# TM4C129ENCPDT register map
File version: 1.0
CPU: CORTEX_M4 1.0, other endian, MPU, FPU, 3 interrupt priority bits
Registers are 32-bit, read-write, reset 0x0 unless marked. A register's access mark holds for its fields unless they carry their own. Offsets are from the block's base; [hi:lo] are bit positions; {n}, {i} and the like mark numbered series.

## HIB — Hibernation module register addresses
Base 0x400FC000
0x00 HIB_RTCC — Hibernation RTC Counter
  [31:0] HIB_RTCC — [31:0] RTC Counter
0x04 HIB_RTCM0 — Hibernation RTC Match 0
  [31:0] HIB_RTCM0 — [31:0] RTC Match 0
0x0C HIB_RTCLD — Hibernation RTC Load
  [31:0] HIB_RTCLD — [31:0] RTC Load
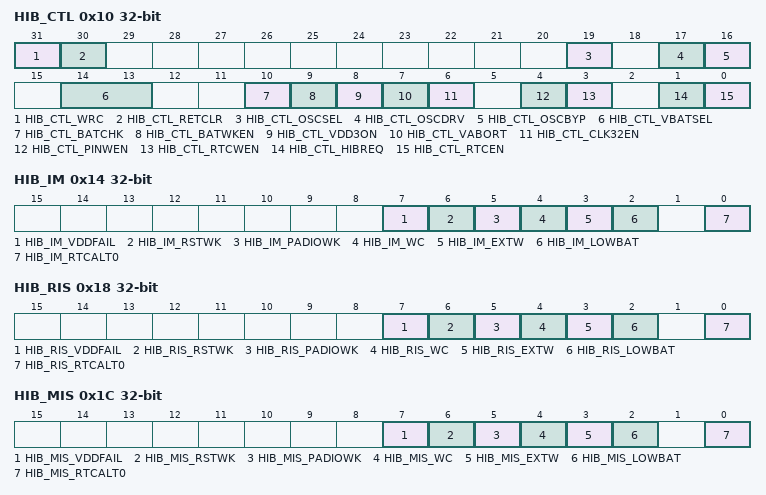
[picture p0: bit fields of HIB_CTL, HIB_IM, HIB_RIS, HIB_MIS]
0x10 HIB_CTL — Hibernation Control
  [31] HIB_CTL_WRC — [31:31] Write Complete/Capable
  [30] HIB_CTL_RETCLR — [30:30] GPIO Retention/Clear
  [19] HIB_CTL_OSCSEL — [19:19] Oscillator Select
  [17] HIB_CTL_OSCDRV — [17:17] Oscillator Drive Capability
  [16] HIB_CTL_OSCBYP — [16:16] Oscillator Bypass
  [14:13] HIB_CTL_VBATSEL — [14:13] Select for Low-Battery Comparator
    0=HIB_CTL_VBATSEL_1_9V (1.9 Volts); 0x2000=HIB_CTL_VBATSEL_2_1V (2.1 Volts (default)); 0x4000=HIB_CTL_VBATSEL_2_3V (2.3 Volts); 0x6000=HIB_CTL_VBATSEL_2_5V (2.5 Volts)
  [10] HIB_CTL_BATCHK — [10:10] Check Battery Status
  [9] HIB_CTL_BATWKEN — [9:9] Wake on Low Battery
  [8] HIB_CTL_VDD3ON — [8:8] VDD Powered
  [7] HIB_CTL_VABORT — [7:7] Power Cut Abort Enable
  [6] HIB_CTL_CLK32EN — [6:6] Clocking Enable
  [4] HIB_CTL_PINWEN — [4:4] External Wake Pin Enable
  [3] HIB_CTL_RTCWEN — [3:3] RTC Wake-up Enable
  [1] HIB_CTL_HIBREQ — [1:1] Hibernation Request
  [0] HIB_CTL_RTCEN — [0:0] RTC Timer Enable
0x14 HIB_IM — Hibernation Interrupt Mask
  [7] HIB_IM_VDDFAIL — [7:7] VDD Fail Interrupt Mask
  [6] HIB_IM_RSTWK — [6:6] Reset Pad I/O Wake-Up Interrupt Mask
  [5] HIB_IM_PADIOWK — [5:5] Pad I/O Wake-Up Interrupt Mask
  [4] HIB_IM_WC — [4:4] External Write Complete/Capable Interrupt Mask
  [3] HIB_IM_EXTW — [3:3] External Wake-Up Interrupt Mask
  [2] HIB_IM_LOWBAT — [2:2] Low Battery Voltage Interrupt Mask
  [0] HIB_IM_RTCALT0 — [0:0] RTC Alert 0 Interrupt Mask
0x18 HIB_RIS — Hibernation Raw Interrupt Status
  [7] HIB_RIS_VDDFAIL — [7:7] VDD Fail Raw Interrupt Status
  [6] HIB_RIS_RSTWK — [6:6] Reset Pad I/O Wake-Up Raw Interrupt Status
  [5] HIB_RIS_PADIOWK — [5:5] Pad I/O Wake-Up Raw Interrupt Status
  [4] HIB_RIS_WC — [4:4] Write Complete/Capable Raw Interrupt Status
  [3] HIB_RIS_EXTW — [3:3] External Wake-Up Raw Interrupt Status
  [2] HIB_RIS_LOWBAT — [2:2] Low Battery Voltage Raw Interrupt Status
  [0] HIB_RIS_RTCALT0 — [0:0] RTC Alert 0 Raw Interrupt Status
0x1C HIB_MIS — Hibernation Masked Interrupt Status
  [7] HIB_MIS_VDDFAIL — [7:7] VDD Fail Interrupt Mask
  [6] HIB_MIS_RSTWK — [6:6] Reset Pad I/O Wake-Up Interrupt Mask
  [5] HIB_MIS_PADIOWK — [5:5] Pad I/O Wake-Up Interrupt Mask
  [4] HIB_MIS_WC — [4:4] Write Complete/Capable Masked Interrupt Status
  [3] HIB_MIS_EXTW — [3:3] External Wake-Up Masked Interrupt Status
  [2] HIB_MIS_LOWBAT — [2:2] Low Battery Voltage Masked Interrupt Status
  [0] HIB_MIS_RTCALT0 — [0:0] RTC Alert 0 Masked Interrupt Status
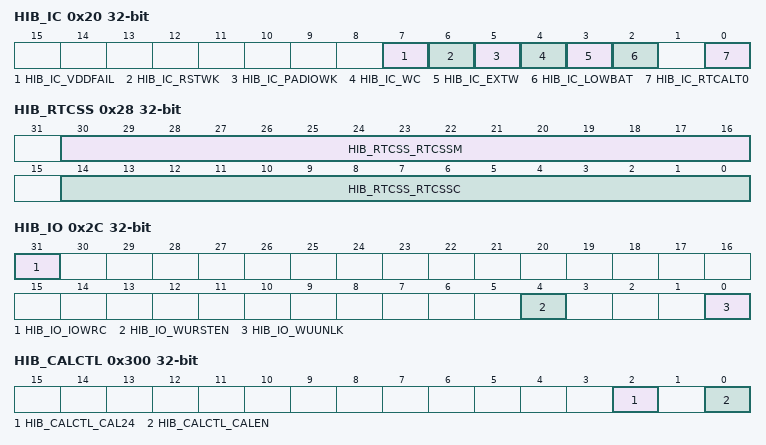
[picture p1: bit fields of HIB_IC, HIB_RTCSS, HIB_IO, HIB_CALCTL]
0x20 HIB_IC — Hibernation Interrupt Clear
  [7] HIB_IC_VDDFAIL — [7:7] VDD Fail Interrupt Clear
  [6] HIB_IC_RSTWK — [6:6] Reset Pad I/O Wake-Up Interrupt Clear
  [5] HIB_IC_PADIOWK — [5:5] Pad I/O Wake-Up Interrupt Clear
  [4] HIB_IC_WC — [4:4] Write Complete/Capable Interrupt Clear
  [3] HIB_IC_EXTW — [3:3] External Wake-Up Interrupt Clear
  [2] HIB_IC_LOWBAT — [2:2] Low Battery Voltage Interrupt Clear
  [0] HIB_IC_RTCALT0 — [0:0] RTC Alert0 Masked Interrupt Clear
0x24 HIB_RTCT — Hibernation RTC Trim
  [15:0] HIB_RTCT_TRIM — [15:0] RTC Trim Value
0x28 HIB_RTCSS — Hibernation RTC Sub Seconds
  [30:16] HIB_RTCSS_RTCSSM — [30:16] RTC Sub Seconds Match
  [14:0] HIB_RTCSS_RTCSSC — [14:0] RTC Sub Seconds Count
0x2C HIB_IO — Hibernation IO Configuration
  [31] HIB_IO_IOWRC — [31:31] I/O Write Complete
  [4] HIB_IO_WURSTEN — [4:4] Reset Wake Source Enable
  [0] HIB_IO_WUUNLK — [0:0] I/O Wake Pad Configuration Enable
0x30 HIB_DATA — Hibernation Data
  [31:0] HIB_DATA_RTD — [31:0] Hibernation Module NV Data
0x300 HIB_CALCTL — Hibernation Calendar Control
  [2] HIB_CALCTL_CAL24 — [2:2] Calendar Mode
  [0] HIB_CALCTL_CALEN — [0:0] RTC Calendar/Counter Mode Select
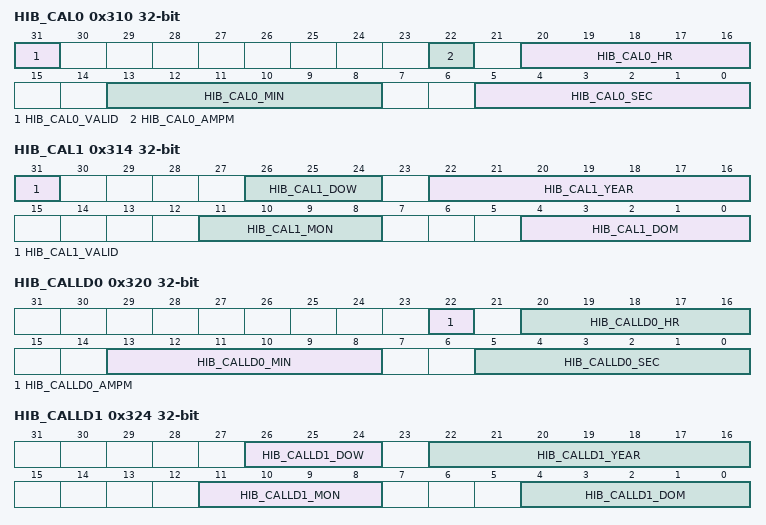
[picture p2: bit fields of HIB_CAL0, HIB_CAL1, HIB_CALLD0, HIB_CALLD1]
0x310 HIB_CAL0 — Hibernation Calendar 0
  [31] HIB_CAL0_VALID — [31:31] Valid Calendar Load
  [22] HIB_CAL0_AMPM — [22:22] AM/PM Designation
  [20:16] HIB_CAL0_HR — [20:16] Hours
  [13:8] HIB_CAL0_MIN — [13:8] Minutes
  [5:0] HIB_CAL0_SEC — [5:0] Seconds
0x314 HIB_CAL1 — Hibernation Calendar 1
  [31] HIB_CAL1_VALID — [31:31] Valid Calendar Load
  [26:24] HIB_CAL1_DOW — [26:24] Day of Week
  [22:16] HIB_CAL1_YEAR — [22:16] Year Value
  [11:8] HIB_CAL1_MON — [11:8] Month
  [4:0] HIB_CAL1_DOM — [4:0] Day of Month
0x320 HIB_CALLD0 — Hibernation Calendar Load 0
  [22] HIB_CALLD0_AMPM — [22:22] AM/PM Designation
  [20:16] HIB_CALLD0_HR — [20:16] Hours
  [13:8] HIB_CALLD0_MIN — [13:8] Minutes
  [5:0] HIB_CALLD0_SEC — [5:0] Seconds
0x324 HIB_CALLD1 — Hibernation Calendar Load
  [26:24] HIB_CALLD1_DOW — [26:24] Day of Week
  [22:16] HIB_CALLD1_YEAR — [22:16] Year Value
  [11:8] HIB_CALLD1_MON — [11:8] Month
  [4:0] HIB_CALLD1_DOM — [4:0] Day of Month
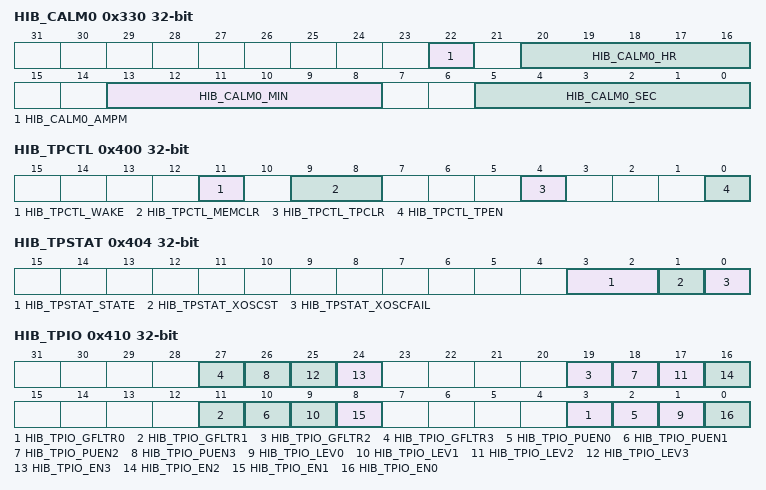
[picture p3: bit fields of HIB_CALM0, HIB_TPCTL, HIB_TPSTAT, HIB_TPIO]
0x330 HIB_CALM0 — Hibernation Calendar Match 0
  [22] HIB_CALM0_AMPM — [22:22] AM/PM Designation
  [20:16] HIB_CALM0_HR — [20:16] Hours
  [13:8] HIB_CALM0_MIN — [13:8] Minutes
  [5:0] HIB_CALM0_SEC — [5:0] Seconds
0x334 HIB_CALM1 — Hibernation Calendar Match 1
  [4:0] HIB_CALM1_DOM — [4:0] Day of Month
0x360 HIB_LOCK — Hibernation Lock
  [31:0] HIB_LOCK_HIBLOCK — [31:0] HIbernate Lock
0x400 HIB_TPCTL — HIB Tamper Control
  [11] HIB_TPCTL_WAKE — [11:11] Wake from Hibernate on a Tamper Event
  [9:8] HIB_TPCTL_MEMCLR — [9:8] HIB Memory Clear on Tamper Event
    0=HIB_TPCTL_MEMCLR_NONE (Do not Clear HIB memory on tamper event); 0x100=HIB_TPCTL_MEMCLR_LOW32 (Clear Lower 32 Bytes of HIB memory on tamper event); 0x200=HIB_TPCTL_MEMCLR_HIGH32 (Clear upper 32 Bytes of HIB memory on tamper event); 0x300=HIB_TPCTL_MEMCLR_ALL (Clear all HIB memory on tamper event)
  [4] HIB_TPCTL_TPCLR — [4:4] Tamper Event Clear
  [0] HIB_TPCTL_TPEN — [0:0] Tamper Module Enable
0x404 HIB_TPSTAT — HIB Tamper Status
  [3:2] HIB_TPSTAT_STATE — [3:2] Tamper Module Status
    0=HIB_TPSTAT_STATE_DISABLED (Tamper disabled); 4=HIB_TPSTAT_STATE_CONFIGED (Tamper configured); 8=HIB_TPSTAT_STATE_ERROR (Tamper pin event occurred)
  [1] HIB_TPSTAT_XOSCST — [1:1] External Oscillator Status
  [0] HIB_TPSTAT_XOSCFAIL — [0:0] External Oscillator Failure
0x410 HIB_TPIO — HIB Tamper I/O Control
  [8n+3] HIB_TPIO_GFLTR{n} (n=0..3) — [{8n+3}:{8n+3}] TMPR{n} Glitch Filtering
  [8n+2] HIB_TPIO_PUEN{n} (n=0..3) — [{8n+2}:{8n+2}] TMPR{n} Internal Weak Pull-up Enable
  [8n+1] HIB_TPIO_LEV{n} (n=0..3) — [{8n+1}:{8n+1}] TMPR{n} Trigger Level
  [24] HIB_TPIO_EN3 — [24:24] TMPR3 Enable
  [16] HIB_TPIO_EN2 — [16:16] TMPR2 Enable
  [8] HIB_TPIO_EN1 — [8:8] TMPR1Enable
  [0] HIB_TPIO_EN0 — [0:0] TMPR0 Enable
0x4E0 HIB_TPLOG0 — HIB Tamper Log 0
  [31:0] HIB_TPLOG0_TIME — [31:0] Tamper Log Calendar Information
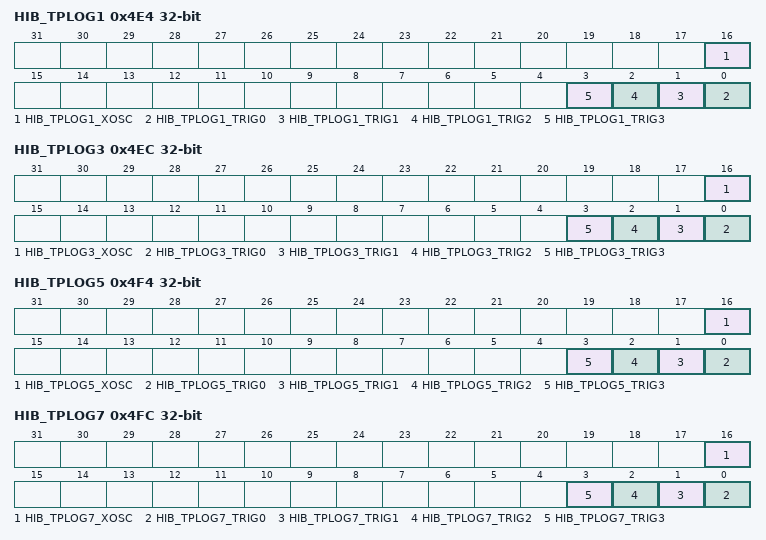
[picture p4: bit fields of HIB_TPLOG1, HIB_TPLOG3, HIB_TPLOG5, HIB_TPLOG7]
0x4E4 HIB_TPLOG1 — HIB Tamper Log 1
  [16] HIB_TPLOG1_XOSC — [16:16] Status of external 32
  [n] HIB_TPLOG1_TRIG{n} (n=0..3) — [{n}:{n}] Status of TMPR[{n}] Trigger
0x4E8 HIB_TPLOG2 — HIB Tamper Log 2
  [31:0] HIB_TPLOG2_TIME — [31:0] Tamper Log Calendar Information
0x4EC HIB_TPLOG3 — HIB Tamper Log 3
  [16] HIB_TPLOG3_XOSC — [16:16] Status of external 32
  [n] HIB_TPLOG3_TRIG{n} (n=0..3) — [{n}:{n}] Status of TMPR[{n}] Trigger
0x4F0 HIB_TPLOG4 — HIB Tamper Log 4
  [31:0] HIB_TPLOG4_TIME — [31:0] Tamper Log Calendar Information
0x4F4 HIB_TPLOG5 — HIB Tamper Log 5
  [16] HIB_TPLOG5_XOSC — [16:16] Status of external 32
  [n] HIB_TPLOG5_TRIG{n} (n=0..3) — [{n}:{n}] Status of TMPR[{n}] Trigger
0x4F8 HIB_TPLOG6 — HIB Tamper Log 6
  [31:0] HIB_TPLOG6_TIME — [31:0] Tamper Log Calendar Information
0x4FC HIB_TPLOG7 — HIB Tamper Log 7
  [16] HIB_TPLOG7_XOSC — [16:16] Status of external 32
  [n] HIB_TPLOG7_TRIG{n} (n=0..3) — [{n}:{n}] Status of TMPR[{n}] Trigger
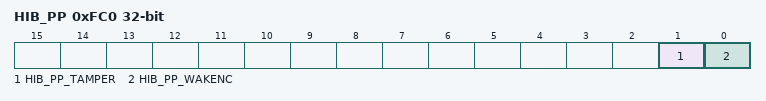
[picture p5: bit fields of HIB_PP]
0xFC0 HIB_PP — Hibernation Peripheral Properties
  [1] HIB_PP_TAMPER — [1:1] Tamper Pin Presence
  [0] HIB_PP_WAKENC — [0:0] Wake Pin Presence
0xFC8 HIB_CC — Hibernation Clock Control
  [0] HIB_CC_SYSCLKEN — [0:0] RTCOSC to System Clock Enable
